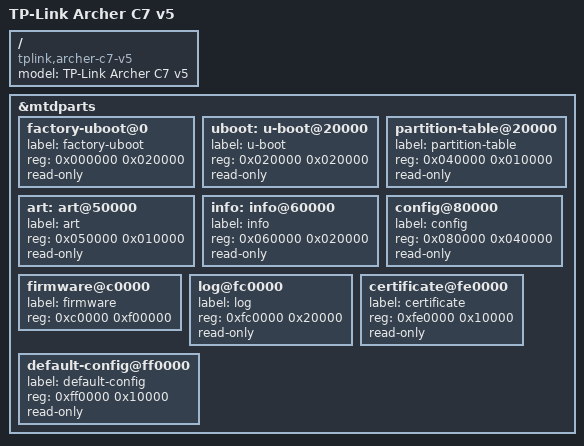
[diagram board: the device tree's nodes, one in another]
// SPDX-License-Identifier: GPL-2.0-or-later OR MIT
/dts-v1/;

#include "qca9563_tplink_archer-x7-v4-v5.dtsi"

/ {
	compatible = "tplink,archer-c7-v5", "qca,qca9563";
	model = "TP-Link Archer C7 v5";
};

&mtdparts {
	factory-uboot@0 {
		label = "factory-uboot";
		reg = <0x000000 0x020000>;
		read-only;
	};

	uboot: u-boot@20000 {
		label = "u-boot";
		reg = <0x020000 0x020000>;
		read-only;
	};

	partition-table@20000 {
		label = "partition-table";
		reg = <0x040000 0x010000>;
		read-only;
	};

	art: art@50000 {
		label = "art";
		reg = <0x050000 0x010000>;
		read-only;
	};

	info: info@60000 {
		label = "info";
		reg = <0x060000 0x020000>;
		read-only;
	};

	config@80000 {
		label = "config";
		reg = <0x080000 0x040000>;
		read-only;
	};

	firmware@c0000 {
		label = "firmware";
		reg = <0xc0000 0xf00000>;
	};

	log@fc0000 {
		label = "log";
		reg = <0xfc0000 0x20000>;
		read-only;
	};

	certificate@fe0000 {
		label = "certificate";
		reg = <0xfe0000 0x10000>;
		read-only;
	};

	default-config@ff0000 {
		label = "default-config";
		reg = <0xff0000 0x10000>;
		read-only;
	};
};
